VERSION ""

NS_ :

BU_: EBCM ADAS PCM EPS VSA SCM BDY XXX EPB EON

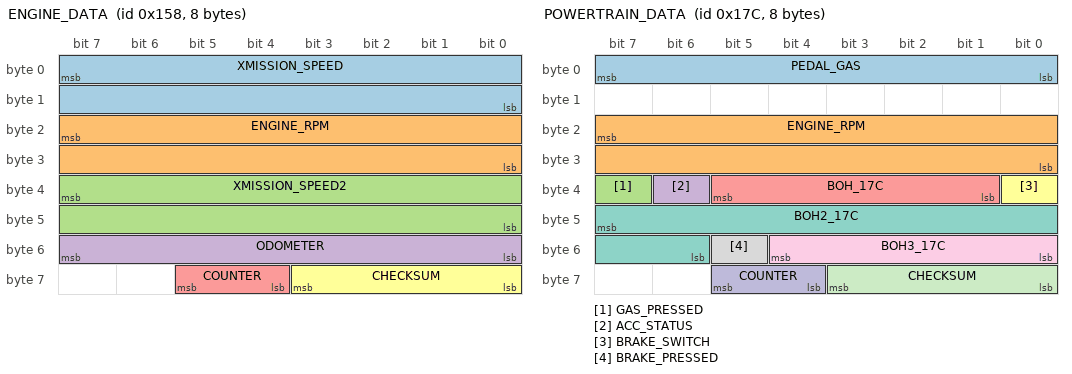
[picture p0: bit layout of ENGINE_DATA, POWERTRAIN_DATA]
BO_ 344 ENGINE_DATA: 8 PCM
 SG_ XMISSION_SPEED : 7|16@0+ (0.01,0) [0|250] "kph" EON
 SG_ ENGINE_RPM : 23|16@0+ (1,0) [0|15000] "rpm" EON
 SG_ XMISSION_SPEED2 : 39|16@0+ (0.01,0) [0|250] "kph" EON
 SG_ ODOMETER : 55|8@0+ (10,0) [0|2550] "m" XXX
 SG_ COUNTER : 61|2@0+ (1,0) [0|3] "" EON
 SG_ CHECKSUM : 59|4@0+ (1,0) [0|15] "" EON

BO_ 380 POWERTRAIN_DATA: 8 PCM
 SG_ PEDAL_GAS : 7|8@0+ (1,0) [0|255] "" EON
 SG_ ENGINE_RPM : 23|16@0+ (1,0) [0|15000] "rpm" EON
 SG_ GAS_PRESSED : 39|1@0+ (1,0) [0|1] "" EON
 SG_ ACC_STATUS : 38|1@0+ (1,0) [0|1] "rpm" EON
 SG_ BOH_17C : 37|5@0+ (1,0) [0|1] "rpm" EON
 SG_ BRAKE_SWITCH : 32|1@0+ (1,0) [0|1] "rpm" EON
 SG_ BOH2_17C : 47|10@0+ (1,0) [0|1] "rpm" EON
 SG_ BRAKE_PRESSED : 53|1@0+ (1,0) [0|1] "" EON
 SG_ BOH3_17C : 52|5@0+ (1,0) [0|1] "rpm" EON
 SG_ COUNTER : 61|2@0+ (1,0) [0|3] "" EON
 SG_ CHECKSUM : 59|4@0+ (1,0) [0|3] "" EON

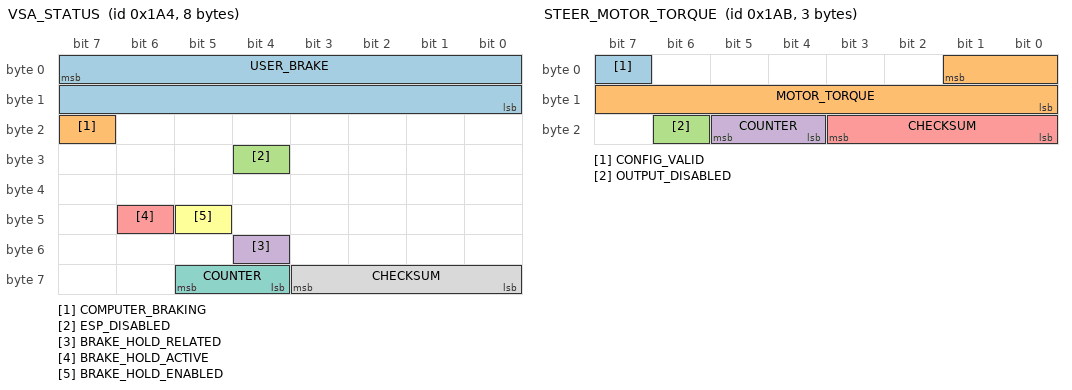
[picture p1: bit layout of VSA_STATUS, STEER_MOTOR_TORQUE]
BO_ 420 VSA_STATUS: 8 VSA
 SG_ USER_BRAKE : 7|16@0+ (0.015625,-1.609375) [0|1000] "" EON
 SG_ COMPUTER_BRAKING : 23|1@0+ (1,0) [0|1] "" EON
 SG_ ESP_DISABLED : 28|1@0+ (1,0) [0|1] "" EON
 SG_ BRAKE_HOLD_RELATED : 52|1@0+ (1,0) [0|1] "" XXX
 SG_ BRAKE_HOLD_ACTIVE : 46|1@0+ (1,0) [0|1] "" EON
 SG_ BRAKE_HOLD_ENABLED : 45|1@0+ (1,0) [0|1] "" EON
 SG_ COUNTER : 61|2@0+ (1,0) [0|3] "" EON
 SG_ CHECKSUM : 59|4@0+ (1,0) [0|15] "" EON

BO_ 427 STEER_MOTOR_TORQUE: 3 EPS
 SG_ CONFIG_VALID : 7|1@0+ (1,0) [0|1] "" EON
 SG_ MOTOR_TORQUE : 1|10@0+ (1,0) [0|256] "" EON
 SG_ OUTPUT_DISABLED : 22|1@0+ (1,0) [0|1] "" EON
 SG_ COUNTER : 21|2@0+ (1,0) [0|3] "" EON
 SG_ CHECKSUM : 19|4@0+ (1,0) [0|15] "" EON

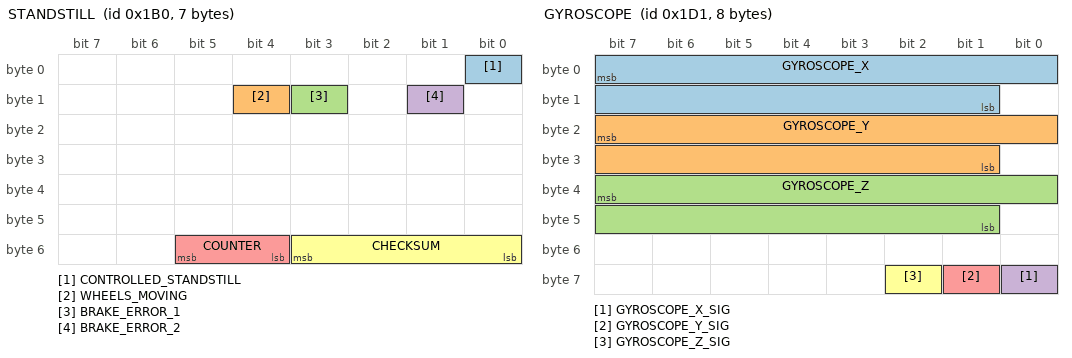
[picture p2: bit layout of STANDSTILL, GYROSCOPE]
BO_ 432 STANDSTILL: 7 VSA
 SG_ CONTROLLED_STANDSTILL : 0|1@0+ (1,0) [0|1] "" EON
 SG_ WHEELS_MOVING : 12|1@0+ (1,0) [0|1] "" EON
 SG_ BRAKE_ERROR_1 : 11|1@0+ (1,0) [0|1] "" EON
 SG_ BRAKE_ERROR_2 : 9|1@0+ (1,0) [0|1] "" EON
 SG_ COUNTER : 53|2@0+ (1,0) [0|3] "" EON
 SG_ CHECKSUM : 51|4@0+ (1,0) [0|3] "" EON

BO_ 464 WHEEL_SPEEDS: 8 VSA
 SG_ WHEEL_SPEED : 7|15@0+ (0.01,0) [0|250] "kph" EON

BO_ 465 GYROSCOPE: 8 VSA
 SG_ GYROSCOPE_X : 7|15@0+ (0.01,0) [0|99999] "rad/s" EON
 SG_ GYROSCOPE_Y : 23|15@0+ (0.01,0) [0|99999] "rad/s" EON
 SG_ GYROSCOPE_Z : 39|15@0+ (0.01,0) [0|99999] "rad/s" EON
 SG_ GYROSCOPE_X_SIG : 56|1@0+ (1,0) [0|1] "" EON
 SG_ GYROSCOPE_Y_SIG : 57|1@0+ (1,0) [0|1] "" EON
 SG_ GYROSCOPE_Z_SIG : 58|1@0+ (1,0) [0|1] "" EON

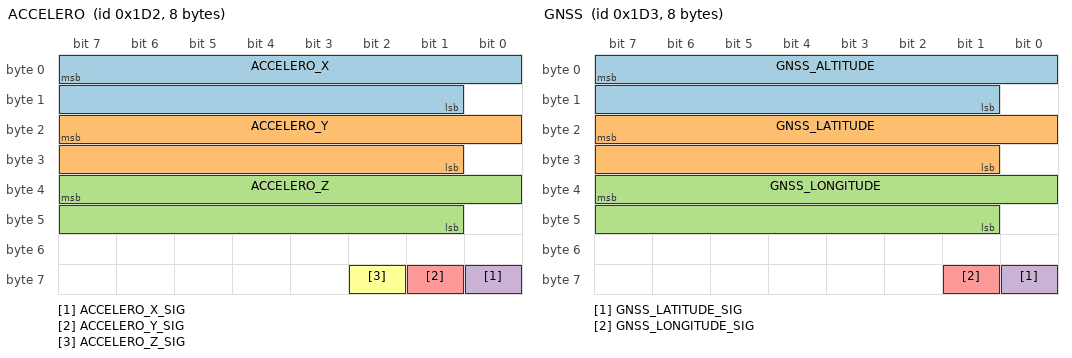
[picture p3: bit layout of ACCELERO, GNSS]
BO_ 466 ACCELERO: 8 VSA
 SG_ ACCELERO_X : 7|15@0+ (0.01,0) [0|99999] "m/s2" EON
 SG_ ACCELERO_Y : 23|15@0+ (0.01,0) [0|99999] "m/s2" EON
 SG_ ACCELERO_Z : 39|15@0+ (0.01,0) [0|99999] "m/s2" EON
 SG_ ACCELERO_X_SIG : 56|1@0+ (1,0) [0|1] "" EON
 SG_ ACCELERO_Y_SIG : 57|1@0+ (1,0) [0|1] "" EON
 SG_ ACCELERO_Z_SIG : 58|1@0+ (1,0) [0|1] "" EON

BO_ 467 GNSS: 8 VSA
 SG_ GNSS_ALTITUDE : 7|15@0+ (0.000001,0) [0|99999] "meters" EON
 SG_ GNSS_LATITUDE : 23|15@0+ (0.000001,0) [0|99999] "degrees -90|90" EON
 SG_ GNSS_LONGITUDE : 39|15@0+ (0.000001,0) [0|99999] "degres -180|180" EON
 SG_ GNSS_LATITUDE_SIG : 56|1@0+ (1,0) [0|1] "" EON
 SG_ GNSS_LONGITUDE_SIG : 57|1@0+ (1,0) [0|1] "" EON

BO_ 468 GEAR_POS: 8 VSA
 SG_ GEAR : 7|15@0+ (1,0) [0|10] "position" EON

BO_ 469 VEHICLE_COLISION: 8 VSA
  SG_ COLISION : 15|15@0+ (1,0) [0|99999] "intensity" EON

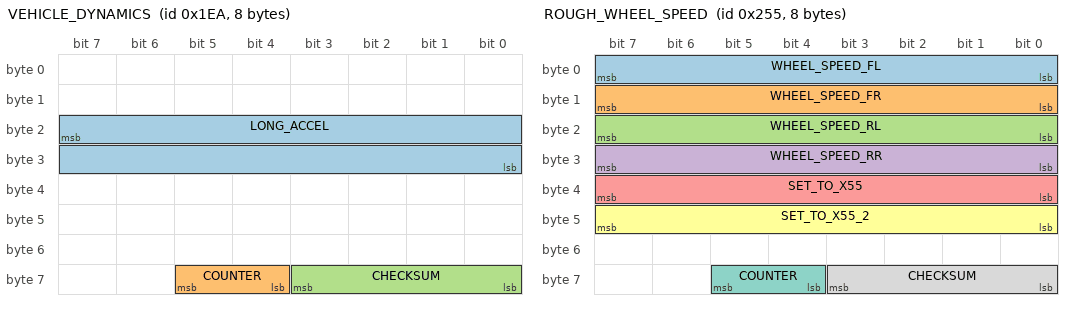
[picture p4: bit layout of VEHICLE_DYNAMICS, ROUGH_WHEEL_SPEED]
BO_ 490 VEHICLE_DYNAMICS: 8 VSA
 SG_ LONG_ACCEL : 23|16@0- (0.0015384,0) [-20|20] "m/s2" EON
 SG_ COUNTER : 61|2@0+ (1,0) [0|3] "" EON
 SG_ CHECKSUM : 59|4@0+ (1,0) [0|3] "" EON

BO_ 506 BRAKE_COMMAND: 8 ADAS
 SG_ COMPUTER_BRAKE : 7|10@0+ (1,0) [0|1] "" EBCM
 SG_ SET_ME_X00 : 13|5@0+ (1,0) [0|1] "" EBCM
 SG_ BRAKE_PUMP_REQUEST : 8|1@0+ (1,0) [0|1] "" EBCM
 SG_ SET_ME_X00_2 : 23|3@0+ (1,0) [0|1] "" EBCM
 SG_ CRUISE_OVERRIDE : 20|1@0+ (1,0) [0|1] "" EBCM
 SG_ SET_ME_X00_3 : 19|1@0+ (1,0) [0|1] "" EBCM
 SG_ CRUISE_FAULT_CMD : 18|1@0+ (1,0) [0|1] "" EBCM
 SG_ CRUISE_CANCEL_CMD : 17|1@0+ (1,0) [0|1] "" EBCM
 SG_ COMPUTER_BRAKE_REQUEST : 16|1@0+ (1,0) [0|1] "" EBCM
 SG_ SET_ME_1 : 31|1@0+ (1,0) [0|1] "" EBCM
 SG_ AEB_REQ_1 : 29|1@0+ (1,0) [0|1] "" XXX
 SG_ AEB_REQ_2 : 26|3@0+ (1,0) [0|7] "" XXX
 SG_ BRAKE_LIGHTS : 39|1@0+ (1,0) [0|1] "" EBCM
 SG_ CRUISE_STATES : 38|7@0+ (1,0) [0|1] "" EBCM
 SG_ CHIME : 47|3@0+ (1,0) [0|7] "" EBCM
 SG_ SET_ME_X00_4 : 44|1@0+ (1,0) [0|1] "" EBCM
 SG_ FCW : 43|2@0+ (1,0) [0|3] "" EBCM
 SG_ AEB_STATUS : 41|2@0+ (1,0) [0|3] "" XXX
 SG_ SET_ME_X00_5 : 55|8@0+ (1,0) [0|0] "" EBCM
 SG_ COUNTER : 61|2@0+ (1,0) [0|3] "" EBCM
 SG_ CHECKSUM : 59|4@0+ (1,0) [0|15] "" EBCM

BO_ 597 ROUGH_WHEEL_SPEED: 8 VSA
 SG_ WHEEL_SPEED_FL : 7|8@0+ (1,0) [0|255] "mph" EON
 SG_ WHEEL_SPEED_FR : 15|8@0+ (1,0) [0|255] "mph" EON
 SG_ WHEEL_SPEED_RL : 23|8@0+ (1,0) [0|255] "mph" EON
 SG_ WHEEL_SPEED_RR : 31|8@0+ (1,0) [0|255] "mph" EON
 SG_ SET_TO_X55 : 39|8@0+ (1,0) [0|255] "" EON
 SG_ SET_TO_X55_2 : 47|8@0+ (1,0) [0|255] "" EON
 SG_ COUNTER : 61|2@0+ (1,0) [0|3] "" EON
 SG_ CHECKSUM : 59|4@0+ (1,0) [0|15] "" EON

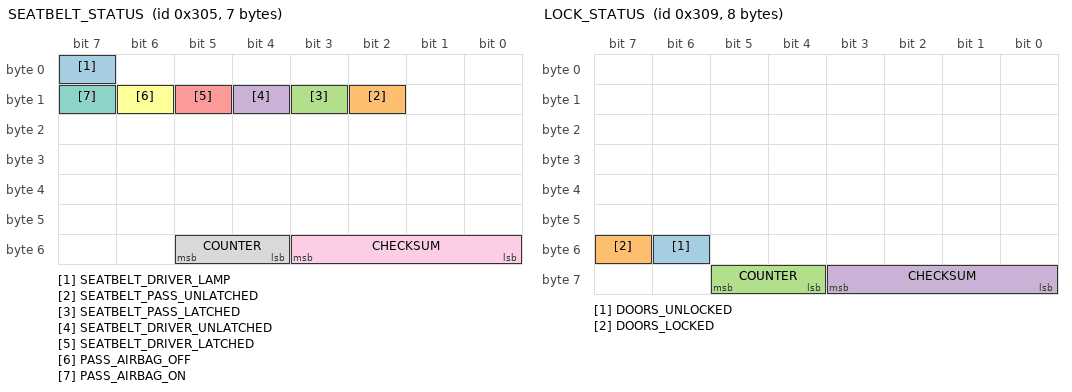
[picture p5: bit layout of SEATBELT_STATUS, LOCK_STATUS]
BO_ 773 SEATBELT_STATUS: 7 BDY
 SG_ SEATBELT_DRIVER_LAMP : 7|1@0+ (1,0) [0|1] "" EON
 SG_ SEATBELT_PASS_UNLATCHED : 10|1@0+ (1,0) [0|1] "" EON
 SG_ SEATBELT_PASS_LATCHED : 11|1@0+ (1,0) [0|1] "" EON
 SG_ SEATBELT_DRIVER_UNLATCHED : 12|1@0+ (1,0) [0|1] "" EON
 SG_ SEATBELT_DRIVER_LATCHED : 13|1@0+ (1,0) [0|1] "" EON
 SG_ PASS_AIRBAG_OFF : 14|1@0+ (1,0) [0|1] "" EON
 SG_ PASS_AIRBAG_ON : 15|1@0+ (1,0) [0|1] "" EON
 SG_ COUNTER : 53|2@0+ (1,0) [0|3] "" EON
 SG_ CHECKSUM : 51|4@0+ (1,0) [0|3] "" EON

BO_ 777 LOCK_STATUS: 8 XXX
 SG_ DOORS_UNLOCKED : 54|1@0+ (1,0) [0|1] "" EON
 SG_ DOORS_LOCKED : 55|1@0+ (1,0) [0|1] "" EON
 SG_ COUNTER : 61|2@0+ (1,0) [0|3] "" EON
 SG_ CHECKSUM : 59|4@0+ (1,0) [0|3] "" EON

BO_ 780 ACC_HUD: 8 ADAS
 SG_ PCM_SPEED : 7|16@0+ (0.01,0) [0|250] "kph" BDY
 SG_ PCM_GAS : 23|8@0+ (1,0) [0|127] "" BDY
 SG_ CRUISE_SPEED : 31|8@0+ (1,0) [0|255] "" BDY
 SG_ DTC_MODE : 39|1@0+ (1,0) [0|1] "" BDY
 SG_ BOH : 38|1@0+ (1,0) [0|1] "" BDY
 SG_ ACC_PROBLEM : 37|1@0+ (1,0) [0|1] "" BDY
 SG_ FCM_OFF : 36|1@0+ (1,0) [0|1] "" BDY
 SG_ FCM_OFF_2 : 35|1@0+ (1,0) [0|1] "" BDY
 SG_ FCM_PROBLEM : 34|1@0+ (1,0) [0|1] "" BDY
 SG_ RADAR_OBSTRUCTED : 33|1@0+ (1,0) [0|1] "" BDY
 SG_ ENABLE_MINI_CAR : 32|1@0+ (1,0) [0|1] "" BDY
 SG_ HUD_DISTANCE : 47|2@0+ (1,0) [0|3] "" BDY
 SG_ HUD_LEAD : 45|2@0+ (1,0) [0|3] "" BDY
 SG_ BOH_3 : 43|1@0+ (1,0) [0|3] "" BDY
 SG_ BOH_4 : 42|1@0+ (1,0) [0|3] "" BDY
 SG_ BOH_5 : 41|1@0+ (1,0) [0|3] "" BDY
 SG_ CRUISE_CONTROL_LABEL : 40|1@0+ (1,0) [0|3] "" BDY
 SG_ SET_ME_X01_2 : 55|1@0+ (1,0) [0|1] "" BDY
 SG_ IMPERIAL_UNIT : 54|1@0+ (1,0) [0|1] "" BDY
 SG_ HUD_DISTANCE_3 : 52|1@0+ (1,0) [0|1] "" BDY
 SG_ CHIME : 51|3@0+ (1,0) [0|1] "" BDY
 SG_ SET_ME_X01 : 48|1@0+ (1,0) [0|1] "" BDY
 SG_ ICONS : 63|2@0+ (1,0) [0|1] "" BDY
 SG_ COUNTER : 61|2@0+ (1,0) [0|3] "" BDY
 SG_ CHECKSUM : 59|4@0+ (1,0) [0|3] "" BDY

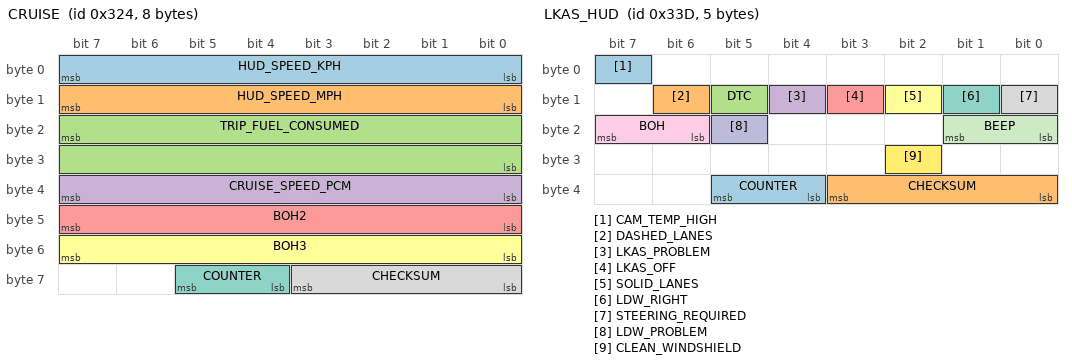
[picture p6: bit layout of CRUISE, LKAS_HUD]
BO_ 804 CRUISE: 8 PCM
 SG_ HUD_SPEED_KPH : 7|8@0+ (1,0) [0|255] "kph" EON
 SG_ HUD_SPEED_MPH : 15|8@0+ (1,0) [0|255] "mph" EON
 SG_ TRIP_FUEL_CONSUMED : 23|16@0+ (1,0) [0|255] "" EON
 SG_ CRUISE_SPEED_PCM : 39|8@0+ (1,0) [0|255] "" EON
 SG_ BOH2 : 47|8@0- (1,0) [0|255] "" EON
 SG_ BOH3 : 55|8@0+ (1,0) [0|255] "" EON
 SG_ COUNTER : 61|2@0+ (1,0) [0|3] "" EON
 SG_ CHECKSUM : 59|4@0+ (1,0) [0|3] "" EON

BO_ 829 LKAS_HUD: 5 ADAS
 SG_ CAM_TEMP_HIGH : 7|1@0+ (1,0) [0|255] "" BDY
 SG_ DASHED_LANES : 14|1@0+ (1,0) [0|1] "" BDY
 SG_ DTC : 13|1@0+ (1,0) [0|1] "" BDY
 SG_ LKAS_PROBLEM : 12|1@0+ (1,0) [0|1] "" BDY
 SG_ LKAS_OFF : 11|1@0+ (1,0) [0|1] "" BDY
 SG_ SOLID_LANES : 10|1@0+ (1,0) [0|1] "" BDY
 SG_ LDW_RIGHT : 9|1@0+ (1,0) [0|1] "" BDY
 SG_ STEERING_REQUIRED : 8|1@0+ (1,0) [0|1] "" BDY
 SG_ BOH : 23|2@0+ (1,0) [0|4] "" BDY
 SG_ LDW_PROBLEM : 21|1@0+ (1,0) [0|1] "" BDY
 SG_ BEEP : 17|2@0+ (1,0) [0|1] "" BDY
 SG_ CLEAN_WINDSHIELD : 26|1@0+ (1,0) [0|1] "" BDY
 SG_ COUNTER : 37|2@0+ (1,0) [0|3] "" BDY
 SG_ CHECKSUM : 35|4@0+ (1,0) [0|15] "" BDY

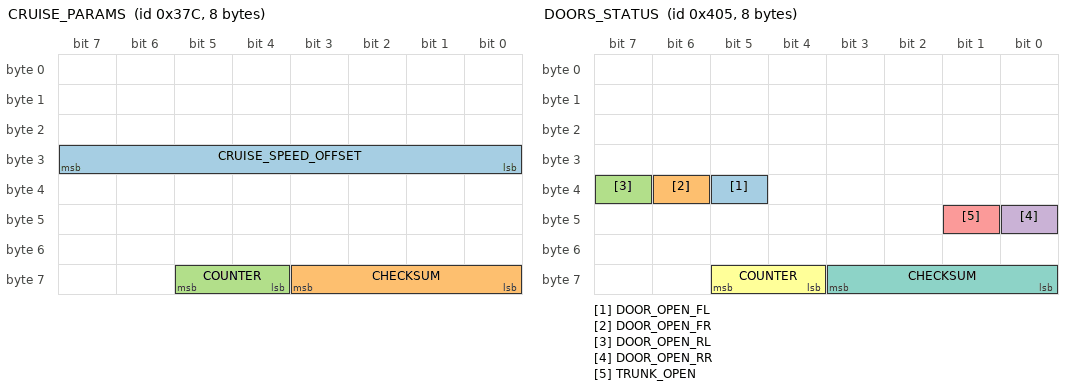
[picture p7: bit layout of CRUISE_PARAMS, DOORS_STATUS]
BO_ 892 CRUISE_PARAMS: 8 PCM
 SG_ CRUISE_SPEED_OFFSET : 31|8@0- (0.1,0) [-128|127] "kph" EON
 SG_ CHECKSUM : 59|4@0+ (1,0) [0|3] "" EON
 SG_ COUNTER : 61|2@0+ (1,0) [0|3] "" EON

BO_ 1029 DOORS_STATUS: 8 BDY
 SG_ DOOR_OPEN_FL : 37|1@0+ (1,0) [0|1] "" EON
 SG_ DOOR_OPEN_FR : 38|1@0+ (1,0) [0|1] "" EON
 SG_ DOOR_OPEN_RL : 39|1@0+ (1,0) [0|1] "" EON
 SG_ DOOR_OPEN_RR : 40|1@0+ (1,0) [0|1] "" EON
 SG_ TRUNK_OPEN : 41|1@0+ (1,0) [0|1] "" EON
 SG_ COUNTER : 61|2@0+ (1,0) [0|3] "" EON
 SG_ CHECKSUM : 59|4@0+ (1,0) [0|3] "" EON

CM_ SG_ 490 LONG_ACCEL "wheel speed derivative, noisy and zero snapping";
CM_ SG_ 506 AEB_REQ_1 "set for duration of suspected AEB event";
CM_ SG_ 773 PASS_AIRBAG_ON "Might just be indicator light";
CM_ SG_ 773 PASS_AIRBAG_OFF "Might just be indicator light";
CM_ SG_ 780 CRUISE_SPEED "255 = no speed";
CM_ SG_ 804 CRUISE_SPEED_PCM "255 = no speed";
CM_ SG_ 829 BEEP "beeps are pleasant, chimes are for warnngs etc...";

VAL_ 506 FCW 3 "fcw" 2 "fcw" 1 "fcw" 0 "no_fcw" ;
VAL_ 506 CHIME 4 "double_chime" 3 "single_chime" 2 "continuous_chime" 1 "repeating_chime" 0 "no_chime" ;
VAL_ 506 AEB_STATUS 3 "aeb_prepare" 2 "aeb_ready" 1 "aeb_braking" 0 "no_aeb" ;
VAL_ 780 CRUISE_SPEED 255 "no_speed" 252 "stopped" ;
VAL_ 780 HUD_LEAD 3 "acc_off" 2 "solid_car" 1 "dashed_car" 0 "no_car" ;
VAL_ 829 BEEP 3 "single_beep" 2 "triple_beep" 1 "repeated_beep" 0 "no_beep" ;
